# netx90_app register map
File version: 1.0
CPU: CM4 r0p1, little endian, MPU, FPU, 4 interrupt priority bits, 78 interrupts
Registers are 32-bit, read-write, reset 0x0 unless marked. A register's access mark holds for its fields unless they carry their own. Offsets are from the block's base; [hi:lo] are bit positions; {n}, {i} and the like mark numbered series.

## iflash_cfg2
Base 0xFF401400
0x00 buffer_read_ahead_instructions — read ahead on instruction channel of flash controller max read ahead = buffer lines - 1
  [31:0] val — read ahead on instruction channel of flash controller
0x04 buffer_read_ahead_data — read ahead on data channel of flash controller max read ahead = buffer lines - 1
  [31:0] val — read ahead on data channel of flash controller
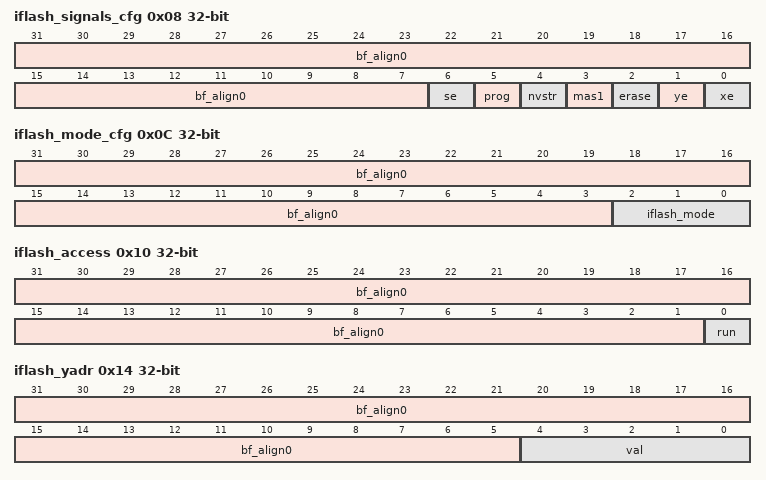
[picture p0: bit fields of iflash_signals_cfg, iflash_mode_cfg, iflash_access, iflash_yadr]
0x08 iflash_signals_cfg (reset mask 0x7F) — no Register description
  [31:7] bf_align0 — bitField alignment value for aeabi compatibility
  [6] se — flash clock
  [5] prog — defines program cycle
  [4] nvstr — defines non-volatile store cycle
  [3] mas1 — defines mass erase cycle
  [2] erase — defines erase cycle
  [1] ye — y address enable
  [0] xe — x address enable
0x0C iflash_mode_cfg (reset mask 0x7) — no Register description
  [31:3] bf_align0 — bitField alignment value for aeabi compatibility
  [2:0] iflash_mode — 3'b000 READ_MODE / 3'b001 PROGRAM_MODE / 3'b010 ERASE_MODE / 3'b011 MASS_ERASE_MODE / 3'b100 MANUAL_MODE
0x10 iflash_access ro (reset mask 0x1) — read only for the ready bit, write 1 to start access flash action depends on iflash_mode_cfg
  [31:1] bf_align0 — bitField alignment value for aeabi compatibility
  [0] run — write 1 to start accesss, poll until set to 0 for finsh
0x14 iflash_yadr (reset mask 0x1F) — Y address of flash controller not all bits are used see: implementation size of flash
  [31:5] bf_align0 — bitField alignment value for aeabi compatibility
  [4:0] val — Y address of flash controller
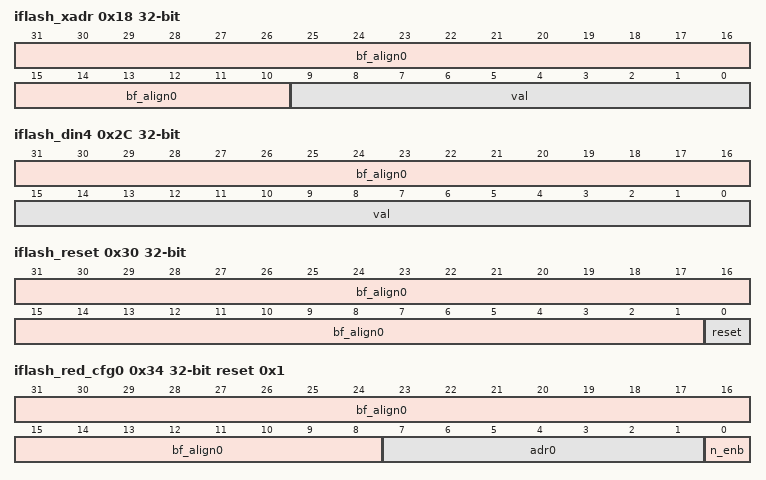
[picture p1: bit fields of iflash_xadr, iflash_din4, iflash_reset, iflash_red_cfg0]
0x18 iflash_xadr (reset mask 0x3FF) — X address of flash controller not all bits are used see: implementation size of flash
  [31:10] bf_align0 — bitField alignment value for aeabi compatibility
  [9:0] val — X address of flash controller
{0x1C+4i} iflash_din{i} (i=0..3) — data[{32i+31}:{32i}] of din flash controller
  [31:0] val
0x2C iflash_din4 (reset mask 0xFFFF) — in manual mode for din data[143:128] of din flash controller
  [31:16] bf_align0 — bitField alignment value for aeabi compatibility
  [15:0] val — data[143:128] of din flash controller
0x30 iflash_reset (reset mask 0x1) — reset flash controller
  [31:1] bf_align0 — bitField alignment value for aeabi compatibility
  [0] reset — 1= reset; 0= release reset
0x34 iflash_red_cfg0 reset 0x1 (reset mask 0xFF) — enable redundancy page XADR[9:3]
  [31:8] bf_align0 — bitField alignment value for aeabi compatibility
  [7:1] adr0 — XADR to compare
  [0] n_enb — 0= enable XADR compare; 1= disable XADR compare
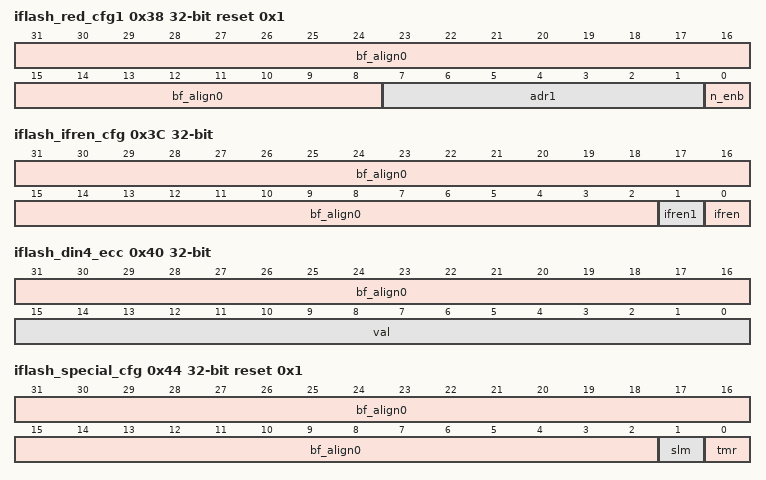
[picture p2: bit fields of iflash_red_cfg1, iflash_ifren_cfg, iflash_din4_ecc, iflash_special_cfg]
0x38 iflash_red_cfg1 reset 0x1 (reset mask 0xFF) — enable redundancy page XADR[9:3]
  [31:8] bf_align0 — bitField alignment value for aeabi compatibility
  [7:1] adr1 — XADR to compare
  [0] n_enb — 0= enable XADR compare; 1= disable XADR compare
0x3C iflash_ifren_cfg (reset mask 0x3) — no Register description
  [31:2] bf_align0 — bitField alignment value for aeabi compatibility
  [1] ifren1 — information1 block enable for read only
  [0] ifren — information block enable
0x40 iflash_din4_ecc ro (reset mask 0xFFFF) — in manual mode for ecc calculation of din3..0
  [31:16] bf_align0 — bitField alignment value for aeabi compatibility
  [15:0] val — ecc of din3..0 flash controller
0x44 iflash_special_cfg reset 0x1 (reset mask 0x3) — no Register description
  [31:2] bf_align0 — bitField alignment value for aeabi compatibility
  [1] slm — sleep mode
  [0] tmr — test mode
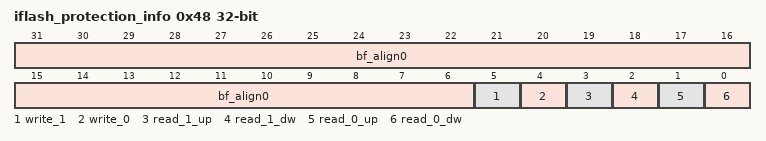
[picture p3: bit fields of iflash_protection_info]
0x48 iflash_protection_info (reset mask 0x3F) — This register is lockable by asic_ctrl_com.netx_lock-lock_system_cfg.
  [31:6] bf_align0 — bitField alignment value for aeabi compatibility
  [5] write_1 — protect infopage 1 4k page for write
  [4] write_0 — protect infopage 0 4k page for write
  [3] read_1_up — protect infopage 1 upper 2k page for read
  [2] read_1_dw — protect infopage 1 lower 2k page for read
  [1] read_0_up — protect infopage 0 upper 2k page for read
  [0] read_0_dw — protect infopage 0 lower 2k page for read
